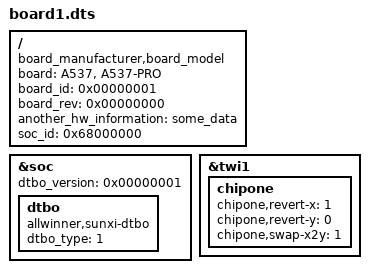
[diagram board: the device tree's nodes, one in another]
/* SPDX-License-Identifier: GPL-2.0-or-later */

/dts-v1/;
/plugin/;
/ {
  board = "A537", "A537-PRO";

  /* As DTS design, these properties only for loader, won't overlay */
  compatible = "board_manufacturer,board_model";

  /* These properties are examples */
  board_id = <0x00000001>;
  board_rev = <0x00000000>;
  another_hw_information = "some_data";
  soc_id = <0x68000000>;

};

&soc {
	dtbo_version = <0x00000001>;
	dtbo{
		compatible = "allwinner,sunxi-dtbo";
		dtbo_type = <1>;
	};
};

&twi1 {
	chipone {
		chipone,revert-x = <1>;
		chipone,revert-y = <0>;
		chipone,swap-x2y = <1>;
	};
};
